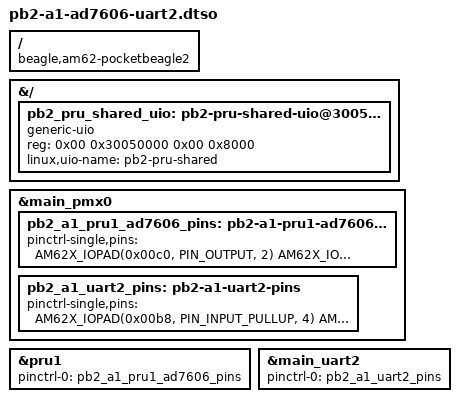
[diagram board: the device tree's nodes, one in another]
/dts-v1/;
/plugin/;

#include "k3-pinctrl.h"

/*
 * PocketBeagle 2 Rev A1 (PB2VA1 / TI AM6254A) PRU1 AD7606 + UART2 Overlay
 *
 * Uses official TI K3 macros (AM62X_IOPAD, PIN_OUTPUT, PIN_INPUT, PIN_INPUT_PULLUP)
 * from BeagleBoard-DeviceTrees k3-pinctrl.h (7e56998024f3520b279ab482dbfa1bb355fa7f3f).
 *
 * PRU1 firmware is loaded via remoteproc (&pru1, compatible = "ti,am625-pru"),
 * while &pruss retains power-domains = <&k3_pds 81 TI_SCI_PD_EXCLUSIVE>.
 * PRU Shared RAM (0x30050000, 32 KB) is exposed via uio_pdrv_genirq
 * (compatible = "generic-uio") without assigning two drivers to &pru1.
 * Target Debian kernel requirements:
 *   - CONFIG_UIO=y|m, CONFIG_UIO_PDRV_GENIRQ=y|m
 *   - uio_pdrv_genirq.of_id=generic-uio (cmdline or modprobe.d)
 *   - pru_rproc must power/start PRUSS before userspace opens /dev/uioX.
 */

/ {
    compatible = "beagle,am62-pocketbeagle2", "ti,am625";
};

&{/} {
    pb2_pru_shared_uio: pb2-pru-shared-uio@30050000 {
        compatible = "generic-uio";
        reg = <0x00 0x30050000 0x00 0x8000>;
        linux,uio-name = "pb2-pru-shared";
        status = "okay";
    };
};

&main_pmx0 {
    pb2_a1_pru1_ad7606_pins: pb2-a1-pru1-ad7606-pins {
        pinctrl-single,pins = <
            AM62X_IOPAD(0x00c0, PIN_OUTPUT, 2)       /* P2.06: PRU1_GPO2  (CONVST)   */
            AM62X_IOPAD(0x00c4, PIN_OUTPUT, 2)       /* P2.08: PRU1_GPO3  (RESET)    */
            AM62X_IOPAD(0x00e8, PIN_OUTPUT, 2)       /* P2.32: PRU1_GPO11 (RD/SCLK)  */
            AM62X_IOPAD(0x00ec, PIN_OUTPUT, 2)       /* P2.30: PRU1_GPO12 (CS_N)     */
            AM62X_IOPAD(0x0174, PIN_INPUT, 4)        /* P2.10: PRU1_GPI4  (BUSY)     */
            AM62X_IOPAD(0x00d0, PIN_INPUT, 3)        /* P2.24: PRU1_GPI6  (DOUTA)    */
            AM62X_IOPAD(0x00d4, PIN_INPUT, 3)        /* P2.33: PRU1_GPI7  (DOUTB)    */
            AM62X_IOPAD(0x00f8, PIN_INPUT, 3)        /* P2.28: PRU1_GPI15 (FRSTDATA) */
        >;
    };

    pb2_a1_uart2_pins: pb2-a1-uart2-pins {
        pinctrl-single,pins = <
            AM62X_IOPAD(0x00b8, PIN_INPUT_PULLUP, 4) /* P2.02: UART2_RXD */
            AM62X_IOPAD(0x00bc, PIN_OUTPUT, 4)       /* P2.04: UART2_TXD */
        >;
    };
};

&pru1 {
    pinctrl-names = "default";
    pinctrl-0 = <&pb2_a1_pru1_ad7606_pins>;
    status = "okay";
};

&main_uart2 {
    pinctrl-names = "default";
    pinctrl-0 = <&pb2_a1_uart2_pins>;
    status = "okay";
};
